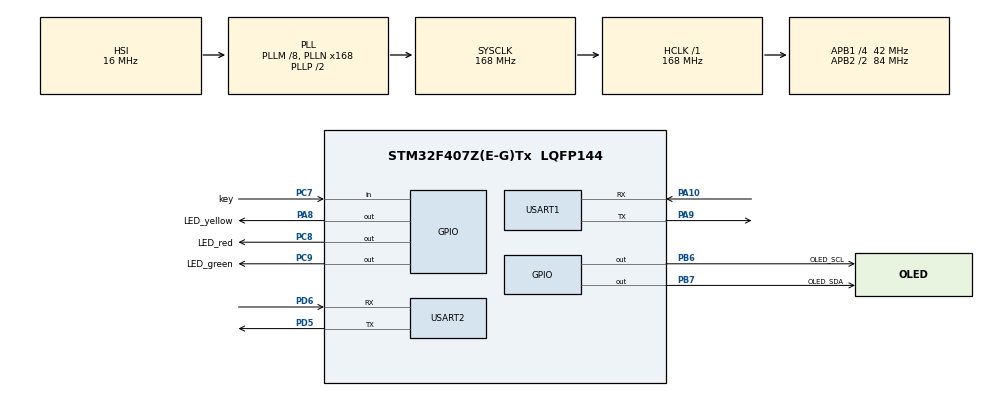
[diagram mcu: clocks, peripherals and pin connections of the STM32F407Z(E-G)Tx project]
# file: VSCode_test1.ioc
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FREERTOS.Queues01=LedQueue,16,LedMessage*,0,Dynamic,NULL,NULL;CommandQueue,16,uint8_t,0,Dynamic,NULL,NULL
FREERTOS.Tasks01=LedTask,24,128,StartLedTask,As weak,NULL,Dynamic,NULL,NULL;KeyTask,40,128,StartKeyTask,As weak,NULL,Dynamic,NULL,NULL;OLEDTask,8,128,StartOLEDTask,As weak,NULL,Dynamic,NULL,NULL;CommandTask,48,128,StartCommandTask,As external,NULL,Dynamic,NULL,NULL
Mcu.Family=STM32F4
Mcu.Name=STM32F407Z(E-G)Tx
Mcu.Package=LQFP144
NVIC.PriorityGroup=NVIC_PRIORITYGROUP_4
NVIC.TIM4_IRQn=true\:0\:0\:true\:false\:true\:false\:false\:true\:true
NVIC.TimeBase=TIM4_IRQn
NVIC.TimeBaseIP=TIM4
NVIC.USART2_IRQn=true\:5\:0\:false\:false\:true\:true\:true\:true\:true
PA10.Mode=Asynchronous
PA10.Signal=USART1_RX
PA13.Mode=Serial_Wire
PA13.Signal=SYS_JTMS-SWDIO
PA14.Mode=Serial_Wire
PA14.Signal=SYS_JTCK-SWCLK
PA8.GPIO_Label=LED_yellow
PA8.Signal=GPIO_Output
PA9.Mode=Asynchronous
PA9.Signal=USART1_TX
PB6.GPIO_Label=OLED_SCL
PB6.GPIO_ModeDefaultOutputPP=GPIO_MODE_OUTPUT_PP
PB6.GPIO_PuPd=GPIO_NOPULL
PB6.Signal=GPIO_Output
PB7.GPIO_Label=OLED_SDA
PB7.Signal=GPIO_Output
PC14-OSC32_IN.Mode=LSE-External-Oscillator
PC14-OSC32_IN.Signal=RCC_OSC32_IN
PC15-OSC32_OUT.Mode=LSE-External-Oscillator
PC15-OSC32_OUT.Signal=RCC_OSC32_OUT
PC7.GPIO_Label=key
PC7.GPIO_PuPd=GPIO_PULLUP
PC7.Signal=GPIO_Input
PC8.GPIO_Label=LED_red
PC8.Signal=GPIO_Output
PC9.GPIO_Label=LED_green
PC9.Signal=GPIO_Output
PD5.Mode=Asynchronous
PD5.Signal=USART2_TX
PD6.Mode=Asynchronous
PD6.Signal=USART2_RX
PH0-OSC_IN.Mode=HSE-External-Oscillator
PH0-OSC_IN.Signal=RCC_OSC_IN
PH1-OSC_OUT.Mode=HSE-External-Oscillator
PH1-OSC_OUT.Signal=RCC_OSC_OUT
ProjectManager.HeapSize=0x200
ProjectManager.StackSize=0x400
ProjectManager.TargetToolchain=CMake
RCC.48MHZClocksFreq_Value=84000000
RCC.AHBFreq_Value=168000000
RCC.APB1CLKDivider=RCC_HCLK_DIV4
RCC.APB1Freq_Value=42000000
RCC.APB1TimFreq_Value=84000000
RCC.APB2CLKDivider=RCC_HCLK_DIV2
RCC.APB2Freq_Value=84000000
RCC.APB2TimFreq_Value=168000000
RCC.CortexFreq_Value=168000000
RCC.HCLKFreq_Value=168000000
RCC.HSE_VALUE=25000000
RCC.HSI_VALUE=16000000
RCC.PLLM=8
RCC.PLLN=168
RCC.RCC_RTC_Clock_Source=RCC_RTCCLKSOURCE_LSE
RCC.SYSCLKFreq_VALUE=168000000
RCC.SYSCLKSource=RCC_SYSCLKSOURCE_PLLCLK
RCC.VCOOutputFreq_Value=336000000
USART1.VirtualMode=VM_ASYNC
USART2.VirtualMode=VM_ASYNC
VP_FREERTOS_VS_CMSIS_V2.Mode=CMSIS_V2
VP_RTC_VS_RTC_Activate.Mode=RTC_Enabled
VP_SYS_VS_tim4.Mode=TIM4
board=custom

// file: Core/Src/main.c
/* USER CODE BEGIN Header */
/**
  ******************************************************************************
  * @file           : main.c
  * @brief          : Main program body
  ******************************************************************************
  * @attention
  *
  * Copyright (c) 2026 STMicroelectronics.
  * All rights reserved.
  *
  * This software is licensed under terms that can be found in the LICENSE file
  * in the root directory of this software component.
  * If no LICENSE file comes with this software, it is provided AS-IS.
  *
  ******************************************************************************
  */
/* USER CODE END Header */
#include "main.h"
#include "cmsis_os.h"
#include "rtc.h"
#include "usart.h"
#include "gpio.h"

/* USER CODE BEGIN Includes */
#include <stdio.h>
#include "oled.h"
#include "commandtask.h"
/* USER CODE END Includes */

void SystemClock_Config(void);
void MX_FREERTOS_Init(void);

int main(void)
{

  /* MCU Configuration--------------------------------------------------------*/

  /* Reset of all peripherals, Initializes the Flash interface and the Systick. */
  HAL_Init();

  /* Configure the system clock */
  SystemClock_Config();

  /* Initialize all configured peripherals */
  MX_GPIO_Init();
  MX_USART1_UART_Init();
  MX_USART2_UART_Init();
  MX_RTC_Init();
  /* USER CODE BEGIN 2 */
  OLED_Init();//初始化OLED
  HAL_UART_Receive_IT(&huart2, (uint8_t *)aRxBuffer, 1);//使能接收中断
  /* USER CODE END 2 */

  /* Init scheduler */
  osKernelInitialize();  /* Call init function for freertos objects (in cmsis_os2.c) */
  MX_FREERTOS_Init();

  /* Start scheduler */
  osKernelStart();

  /* We should never get here as control is now taken by the scheduler */

  /* Infinite loop */
  while (1)
  {

  }
}

void SystemClock_Config(void)
{
  RCC_OscInitTypeDef RCC_OscInitStruct = {0};
  RCC_ClkInitTypeDef RCC_ClkInitStruct = {0};

  /** Configure the main internal regulator output voltage
  */
  __HAL_RCC_PWR_CLK_ENABLE();
  __HAL_PWR_VOLTAGESCALING_CONFIG(PWR_REGULATOR_VOLTAGE_SCALE1);

  /** Initializes the RCC Oscillators according to the specified parameters
  * in the RCC_OscInitTypeDef structure.
  */
  RCC_OscInitStruct.OscillatorType = RCC_OSCILLATORTYPE_HSI|RCC_OSCILLATORTYPE_LSE;
  RCC_OscInitStruct.LSEState = RCC_LSE_ON;
  RCC_OscInitStruct.HSIState = RCC_HSI_ON;
  RCC_OscInitStruct.HSICalibrationValue = RCC_HSICALIBRATION_DEFAULT;
  RCC_OscInitStruct.PLL.PLLState = RCC_PLL_ON;
  RCC_OscInitStruct.PLL.PLLSource = RCC_PLLSOURCE_HSI;
  RCC_OscInitStruct.PLL.PLLM = 8;
  RCC_OscInitStruct.PLL.PLLN = 168;
  RCC_OscInitStruct.PLL.PLLP = RCC_PLLP_DIV2;
  RCC_OscInitStruct.PLL.PLLQ = 4;
  if (HAL_RCC_OscConfig(&RCC_OscInitStruct) != HAL_OK)
  {
    Error_Handler();
  }

  /** Initializes the CPU, AHB and APB buses clocks
  */
  RCC_ClkInitStruct.ClockType = RCC_CLOCKTYPE_HCLK|RCC_CLOCKTYPE_SYSCLK
                              |RCC_CLOCKTYPE_PCLK1|RCC_CLOCKTYPE_PCLK2;
  RCC_ClkInitStruct.SYSCLKSource = RCC_SYSCLKSOURCE_PLLCLK;
  RCC_ClkInitStruct.AHBCLKDivider = RCC_SYSCLK_DIV1;
  RCC_ClkInitStruct.APB1CLKDivider = RCC_HCLK_DIV4;
  RCC_ClkInitStruct.APB2CLKDivider = RCC_HCLK_DIV2;

  if (HAL_RCC_ClockConfig(&RCC_ClkInitStruct, FLASH_LATENCY_5) != HAL_OK)
  {
    Error_Handler();
  }
}

void HAL_TIM_PeriodElapsedCallback(TIM_HandleTypeDef *htim)
{
  if (htim->Instance == TIM4)
  {
    HAL_IncTick();
  }
}

void Error_Handler(void)
{
  __disable_irq();
  while (1)
  {
  }
}

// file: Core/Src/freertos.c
/* USER CODE BEGIN Header */
/**
  ******************************************************************************
  * File Name          : freertos.c
  * Description        : Code for freertos applications
  ******************************************************************************
  * @attention
  *
  * Copyright (c) 2026 STMicroelectronics.
  * All rights reserved.
  *
  * This software is licensed under terms that can be found in the LICENSE file
  * in the root directory of this software component.
  * If no LICENSE file comes with this software, it is provided AS-IS.
  *
  ******************************************************************************
  */
/* USER CODE END Header */

#include "FreeRTOS.h"
#include "task.h"
#include "main.h"
#include "cmsis_os.h"

/* USER CODE BEGIN Includes */
#include "keytask.h"
#include "ledtask.h"
/* USER CODE END Includes */

/* Definitions for LedTask */
osThreadId_t LedTaskHandle;
const osThreadAttr_t LedTask_attributes = {
  .name = "LedTask",
  .stack_size = 128 * 4,
  .priority = (osPriority_t) osPriorityNormal,
};
/* Definitions for KeyTask */
osThreadId_t KeyTaskHandle;
const osThreadAttr_t KeyTask_attributes = {
  .name = "KeyTask",
  .stack_size = 128 * 4,
  .priority = (osPriority_t) osPriorityHigh,
};
/* Definitions for OLEDTask */
osThreadId_t OLEDTaskHandle;
const osThreadAttr_t OLEDTask_attributes = {
  .name = "OLEDTask",
  .stack_size = 128 * 4,
  .priority = (osPriority_t) osPriorityLow,
};
/* Definitions for CommandTask */
osThreadId_t CommandTaskHandle;
const osThreadAttr_t CommandTask_attributes = {
  .name = "CommandTask",
  .stack_size = 128 * 4,
  .priority = (osPriority_t) osPriorityRealtime,
};
/* Definitions for LedQueue */
osMessageQueueId_t LedQueueHandle;
const osMessageQueueAttr_t LedQueue_attributes = {
  .name = "LedQueue"
};
/* Definitions for CommandQueue */
osMessageQueueId_t CommandQueueHandle;
const osMessageQueueAttr_t CommandQueue_attributes = {
  .name = "CommandQueue"
};

void StartLedTask(void *argument);
void StartKeyTask(void *argument);
void StartOLEDTask(void *argument);
extern void StartCommandTask(void *argument);

void MX_FREERTOS_Init(void); /* (MISRA C 2004 rule 8.1) */

void MX_FREERTOS_Init(void) {

  /* Create the queue(s) */
  /* creation of LedQueue */
  LedQueueHandle = osMessageQueueNew (16, sizeof(LedMessage*), &LedQueue_attributes);

  /* creation of CommandQueue */
  CommandQueueHandle = osMessageQueueNew (16, sizeof(uint8_t), &CommandQueue_attributes);

  /* Create the thread(s) */
  /* creation of LedTask */
  LedTaskHandle = osThreadNew(StartLedTask, NULL, &LedTask_attributes);

  /* creation of KeyTask */
  KeyTaskHandle = osThreadNew(StartKeyTask, NULL, &KeyTask_attributes);

  /* creation of OLEDTask */
  OLEDTaskHandle = osThreadNew(StartOLEDTask, NULL, &OLEDTask_attributes);

  /* creation of CommandTask */
  CommandTaskHandle = osThreadNew(StartCommandTask, NULL, &CommandTask_attributes);

}

__weak void StartLedTask(void *argument)
{
  for(;;)
  {
    osDelay(1);
  }
}

__weak void StartKeyTask(void *argument)
{
  for(;;)
  {
    osDelay(1);
  }
}

__weak void StartOLEDTask(void *argument)
{
  for(;;)
  {
    osDelay(1);
  }
}
